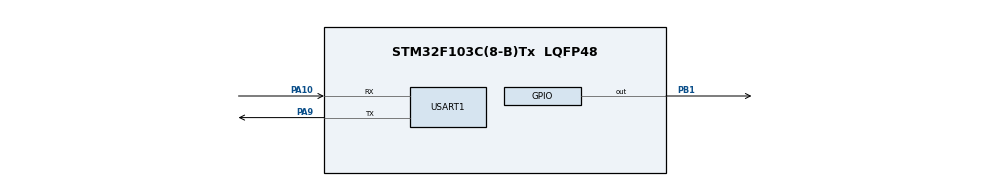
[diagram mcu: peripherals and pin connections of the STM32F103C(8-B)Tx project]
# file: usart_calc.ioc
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FREERTOS.Queues01=problems,64,Problem,NULL,Dynamic,NULL,NULL
FREERTOS.Tasks01=defaultTask,0,512,StartDefaultTask,Default,NULL,Dynamic,NULL,NULL;heartbeatTask,-3,128,heartbeat,Default,NULL,Dynamic,NULL,NULL
FREERTOS.configTOTAL_HEAP_SIZE=16800
Mcu.Family=STM32F1
Mcu.Name=STM32F103C(8-B)Tx
Mcu.Package=LQFP48
NVIC.PriorityGroup=NVIC_PRIORITYGROUP_4
NVIC.USART1_IRQn=true\:5\:0\:false\:false\:true\:true\:true
PA10.Mode=Asynchronous
PA10.Signal=USART1_RX
PA13.Mode=Serial_Wire
PA13.Signal=SYS_JTMS-SWDIO
PA14.Mode=Serial_Wire
PA14.Signal=SYS_JTCK-SWCLK
PA9.Mode=Asynchronous
PA9.Signal=USART1_TX
PB1.Signal=GPIO_Output
ProjectManager.HeapSize=0x200
ProjectManager.StackSize=0x400
ProjectManager.TargetToolchain=SW4STM32
RCC.APB1Freq_Value=8000000
RCC.APB2Freq_Value=8000000
USART1.VirtualMode=VM_ASYNC
VP_FREERTOS_VS_ENABLE.Mode=Enabled
board=usart_calc

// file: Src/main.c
/**
  ******************************************************************************
  * File Name          : main.c
  * Description        : Main program body
  ******************************************************************************
  * This notice applies to any and all portions of this file
  * that are not between comment pairs USER CODE BEGIN and
  * USER CODE END. Other portions of this file, whether
  * inserted by the user or by software development tools
  * are owned by their respective copyright owners.
  *
  * Copyright (c) 2018 STMicroelectronics International N.V.
  * All rights reserved.
  *
  * Redistribution and use in source and binary forms, with or without
  * modification, are permitted, provided that the following conditions are met:
  *
  * 1. Redistribution of source code must retain the above copyright notice,
  *    this list of conditions and the following disclaimer.
  * 2. Redistributions in binary form must reproduce the above copyright notice,
  *    this list of conditions and the following disclaimer in the documentation
  *    and/or other materials provided with the distribution.
  * 3. Neither the name of STMicroelectronics nor the names of other
  *    contributors to this software may be used to endorse or promote products
  *    derived from this software without specific written permission.
  * 4. This software, including modifications and/or derivative works of this
  *    software, must execute solely and exclusively on microcontroller or
  *    microprocessor devices manufactured by or for STMicroelectronics.
  * 5. Redistribution and use of this software other than as permitted under
  *    this license is void and will automatically terminate your rights under
  *    this license.
  *
  * THIS SOFTWARE IS PROVIDED BY STMICROELECTRONICS AND CONTRIBUTORS "AS IS"
  * AND ANY EXPRESS, IMPLIED OR STATUTORY WARRANTIES, INCLUDING, BUT NOT
  * LIMITED TO, THE IMPLIED WARRANTIES OF MERCHANTABILITY, FITNESS FOR A
  * PARTICULAR PURPOSE AND NON-INFRINGEMENT OF THIRD PARTY INTELLECTUAL PROPERTY
  * RIGHTS ARE DISCLAIMED TO THE FULLEST EXTENT PERMITTED BY LAW. IN NO EVENT
  * SHALL STMICROELECTRONICS OR CONTRIBUTORS BE LIABLE FOR ANY DIRECT, INDIRECT,
  * INCIDENTAL, SPECIAL, EXEMPLARY, OR CONSEQUENTIAL DAMAGES (INCLUDING, BUT NOT
  * LIMITED TO, PROCUREMENT OF SUBSTITUTE GOODS OR SERVICES; LOSS OF USE, DATA,
  * OR PROFITS; OR BUSINESS INTERRUPTION) HOWEVER CAUSED AND ON ANY THEORY OF
  * LIABILITY, WHETHER IN CONTRACT, STRICT LIABILITY, OR TORT (INCLUDING
  * NEGLIGENCE OR OTHERWISE) ARISING IN ANY WAY OUT OF THE USE OF THIS SOFTWARE,
  * EVEN IF ADVISED OF THE POSSIBILITY OF SUCH DAMAGE.
  *
  ******************************************************************************
  */

#include "main.h"
#include "stm32f1xx_hal.h"
#include "cmsis_os.h"
#include "usart.h"
#include "gpio.h"

/* USER CODE BEGIN PV */
/* Private variables ---------------------------------------------------------*/

/* USER CODE END PV */

void SystemClock_Config(void);
void MX_FREERTOS_Init(void);

/* USER CODE BEGIN PFP */
/* Private function prototypes -----------------------------------------------*/

/* USER CODE END PFP */

int main(void)
{

  /* MCU Configuration----------------------------------------------------------*/

  /* Reset of all peripherals, Initializes the Flash interface and the Systick. */
  HAL_Init();

  /* Configure the system clock */
  SystemClock_Config();

  /* Initialize all configured peripherals */
  MX_GPIO_Init();
  MX_USART1_UART_Init();

  /* Call init function for freertos objects (in freertos.c) */
  MX_FREERTOS_Init();

  /* Start scheduler */
  osKernelStart();

  /* We should never get here as control is now taken by the scheduler */

  /* Infinite loop */
  while (1)
  {

  }

}

/** System Clock Configuration
*/
void SystemClock_Config(void)
{

  RCC_OscInitTypeDef RCC_OscInitStruct;
  RCC_ClkInitTypeDef RCC_ClkInitStruct;

    /**Initializes the CPU, AHB and APB busses clocks
    */
  RCC_OscInitStruct.OscillatorType = RCC_OSCILLATORTYPE_HSI;
  RCC_OscInitStruct.HSIState = RCC_HSI_ON;
  RCC_OscInitStruct.HSICalibrationValue = 16;
  RCC_OscInitStruct.PLL.PLLState = RCC_PLL_NONE;
  if (HAL_RCC_OscConfig(&RCC_OscInitStruct) != HAL_OK)
  {
    _Error_Handler(__FILE__, __LINE__);
  }

    /**Initializes the CPU, AHB and APB busses clocks
    */
  RCC_ClkInitStruct.ClockType = RCC_CLOCKTYPE_HCLK|RCC_CLOCKTYPE_SYSCLK
                              |RCC_CLOCKTYPE_PCLK1|RCC_CLOCKTYPE_PCLK2;
  RCC_ClkInitStruct.SYSCLKSource = RCC_SYSCLKSOURCE_HSI;
  RCC_ClkInitStruct.AHBCLKDivider = RCC_SYSCLK_DIV1;
  RCC_ClkInitStruct.APB1CLKDivider = RCC_HCLK_DIV1;
  RCC_ClkInitStruct.APB2CLKDivider = RCC_HCLK_DIV1;

  if (HAL_RCC_ClockConfig(&RCC_ClkInitStruct, FLASH_LATENCY_0) != HAL_OK)
  {
    _Error_Handler(__FILE__, __LINE__);
  }

    /**Configure the Systick interrupt time
    */
  HAL_SYSTICK_Config(HAL_RCC_GetHCLKFreq()/1000);

    /**Configure the Systick
    */
  HAL_SYSTICK_CLKSourceConfig(SYSTICK_CLKSOURCE_HCLK);

  /* SysTick_IRQn interrupt configuration */
  HAL_NVIC_SetPriority(SysTick_IRQn, 15, 0);
}

void _Error_Handler(char * file, int line)
{
  while(1)
  {
  }
}

/************************ (C) COPYRIGHT STMicroelectronics *****END OF FILE****/

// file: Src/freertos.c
/**
  ******************************************************************************
  * File Name          : freertos.c
  * Description        : Code for freertos applications
  ******************************************************************************
  * This notice applies to any and all portions of this file
  * that are not between comment pairs USER CODE BEGIN and
  * USER CODE END. Other portions of this file, whether
  * inserted by the user or by software development tools
  * are owned by their respective copyright owners.
  *
  * Copyright (c) 2018 STMicroelectronics International N.V.
  * All rights reserved.
  *
  * Redistribution and use in source and binary forms, with or without
  * modification, are permitted, provided that the following conditions are met:
  *
  * 1. Redistribution of source code must retain the above copyright notice,
  *    this list of conditions and the following disclaimer.
  * 2. Redistributions in binary form must reproduce the above copyright notice,
  *    this list of conditions and the following disclaimer in the documentation
  *    and/or other materials provided with the distribution.
  * 3. Neither the name of STMicroelectronics nor the names of other
  *    contributors to this software may be used to endorse or promote products
  *    derived from this software without specific written permission.
  * 4. This software, including modifications and/or derivative works of this
  *    software, must execute solely and exclusively on microcontroller or
  *    microprocessor devices manufactured by or for STMicroelectronics.
  * 5. Redistribution and use of this software other than as permitted under
  *    this license is void and will automatically terminate your rights under
  *    this license.
  *
  * THIS SOFTWARE IS PROVIDED BY STMICROELECTRONICS AND CONTRIBUTORS "AS IS"
  * AND ANY EXPRESS, IMPLIED OR STATUTORY WARRANTIES, INCLUDING, BUT NOT
  * LIMITED TO, THE IMPLIED WARRANTIES OF MERCHANTABILITY, FITNESS FOR A
  * PARTICULAR PURPOSE AND NON-INFRINGEMENT OF THIRD PARTY INTELLECTUAL PROPERTY
  * RIGHTS ARE DISCLAIMED TO THE FULLEST EXTENT PERMITTED BY LAW. IN NO EVENT
  * SHALL STMICROELECTRONICS OR CONTRIBUTORS BE LIABLE FOR ANY DIRECT, INDIRECT,
  * INCIDENTAL, SPECIAL, EXEMPLARY, OR CONSEQUENTIAL DAMAGES (INCLUDING, BUT NOT
  * LIMITED TO, PROCUREMENT OF SUBSTITUTE GOODS OR SERVICES; LOSS OF USE, DATA,
  * OR PROFITS; OR BUSINESS INTERRUPTION) HOWEVER CAUSED AND ON ANY THEORY OF
  * LIABILITY, WHETHER IN CONTRACT, STRICT LIABILITY, OR TORT (INCLUDING
  * NEGLIGENCE OR OTHERWISE) ARISING IN ANY WAY OUT OF THE USE OF THIS SOFTWARE,
  * EVEN IF ADVISED OF THE POSSIBILITY OF SUCH DAMAGE.
  *
  ******************************************************************************
  */

#include "FreeRTOS.h"
#include "task.h"
#include "cmsis_os.h"

/* USER CODE BEGIN Includes */
#include "stm32f1xx.h"
#include "usart.h"
/* USER CODE END Includes */

osThreadId defaultTaskHandle;
osThreadId heartbeatTaskHandle;
osMessageQId problemsHandle;

/* USER CODE BEGIN Variables */
#define PROBLEM_MAX_SIZE 20
#define TXBUF_SIZE 100

extern int pxHigherPriorityTaskWoken;

typedef uint8_t Problem[PROBLEM_MAX_SIZE];

uint8_t rxBuffer[PROBLEM_MAX_SIZE];
int pos = 0;

uint8_t txBuffer[TXBUF_SIZE];
int txHead = 0;
int txTail = 0;
/* USER CODE END Variables */

void StartDefaultTask(void const * argument);
void heartbeat(void const * argument);

void MX_FREERTOS_Init(void); /* (MISRA C 2004 rule 8.1) */

/* USER CODE BEGIN FunctionPrototypes */
void sendNext();
void sendResponse(const char *msg, int size);
/* USER CODE END FunctionPrototypes */

/* Hook prototypes */

/* Init FreeRTOS */

void MX_FREERTOS_Init(void) {

  /* Create the thread(s) */
  /* definition and creation of defaultTask */
  osThreadDef(defaultTask, StartDefaultTask, osPriorityNormal, 0, 512);
  defaultTaskHandle = osThreadCreate(osThread(defaultTask), NULL);

  /* definition and creation of heartbeatTask */
  osThreadDef(heartbeatTask, heartbeat, osPriorityIdle, 0, 128);
  heartbeatTaskHandle = osThreadCreate(osThread(heartbeatTask), NULL);

  /* Create the queue(s) */
  /* definition and creation of problems */
  osMessageQDef(problems, 64, Problem);
  problemsHandle = osMessageCreate(osMessageQ(problems), NULL);

}

/* StartDefaultTask function */
void StartDefaultTask(void const * argument)
{

  /* USER CODE BEGIN StartDefaultTask */
	configASSERT(HAL_UART_Receive_IT(&huart1, rxBuffer, 1) == HAL_OK);
	Problem problem;
	int a, b;
	char op;
	char resultBuf[12];
	for(;;) {
		configASSERT(xQueueReceive(problemsHandle, &problem, portMAX_DELAY) == pdTRUE);

		int val = sscanf(problem, "%d %c %d", &a, &op, &b);
		if(val != 3) {
			continue;
		}

		//osDelay(100);

		int result = a + b;
		snprintf(resultBuf, sizeof(resultBuf), "%d\n", result);
		sendResponse(resultBuf, strlen(resultBuf));
	}
  /* USER CODE END StartDefaultTask */
}

/* heartbeat function */
void heartbeat(void const * argument)
{
  /* USER CODE BEGIN heartbeat */
	for(;;) {
		HAL_GPIO_TogglePin(GPIOB, GPIO_PIN_1);
		osDelay(500);
	}
  /* USER CODE END heartbeat */
}

/* USER CODE BEGIN Application */
void HAL_UART_RxCpltCallback(UART_HandleTypeDef *huart) {
	if(rxBuffer[pos] == '\n') {
		configASSERT(xQueueSendFromISR(problemsHandle, rxBuffer, &pxHigherPriorityTaskWoken) == pdTRUE);
		pos = 0;
	} else {
		pos++;
	}

	int x = HAL_UART_Receive_IT(&huart1, rxBuffer + pos, 1);
	configASSERT(x == HAL_OK);

	if (pos >= sizeof(rxBuffer)) {
		pos = 0;
	}
}

void sendNext() {
	configASSERT(HAL_UART_Transmit_IT(&huart1, txBuffer + txHead, 1) == HAL_OK);
}

void HAL_UART_TxCpltCallback(UART_HandleTypeDef *huart) {
	txHead = (txHead + 1) % TXBUF_SIZE;

	if(txHead != txTail) {
		sendNext();
	}
}

void sendResponse(const char *msg, int size) {
	portENTER_CRITICAL();
	int notify = txHead == txTail;

	for(int i = 0; i < size; i++) {
		txBuffer[txTail] = msg[i];
		txTail = (txTail + 1) % TXBUF_SIZE;
	}

	if(notify) {
		sendNext();
	}

	portEXIT_CRITICAL();
}

/* USER CODE END Application */

/************************ (C) COPYRIGHT STMicroelectronics *****END OF FILE****/
